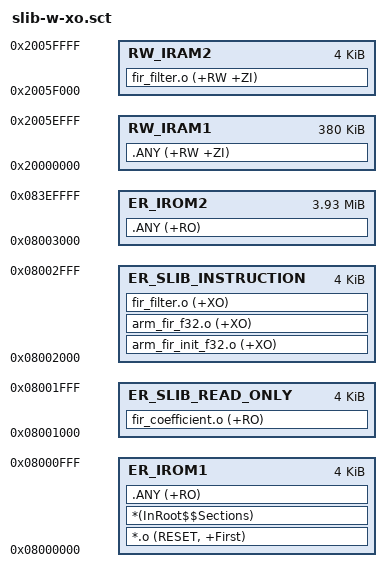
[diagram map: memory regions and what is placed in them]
; *************************************************************
; *** Scatter-Loading Description File generated by uVision ***
; *************************************************************

; this scatter file is used for at32f435zmt7 ( flash size is 4032kb, sector size is 4kb)

LR_IROM1 0x08000000 0x001000  {    ; load region size_region
  ER_IROM1 0x08000000 0x001000  {  ; load address = execution address
   *.o (RESET, +First)
   *(InRoot$$Sections)
   .ANY (+RO)
  }
  
  RW_IRAM1 0x20000000 0x0005F000  {  ; user RW data
   .ANY (+RW +ZI)
  }
  
  RW_IRAM2 0x2005F000 0x00001000  {  ; RAM used for slib code
   fir_filter.o (+RW +ZI) 
  }  
}

LR_SLIB_READ_ONLY 0x08001000 0x00001000  {    ; sLib read-only area
  ER_SLIB_READ_ONLY 0x08001000 0x00001000  {  
   fir_coefficient.o (+RO)   
  }
}

LR_SLIB_INSTRUCTION 0x08002000 0x00001000  {    ; slib instruction area
  ER_SLIB_INSTRUCTION 0x08002000 0x00001000  {  ; load address = execution address
	arm_fir_init_f32.o (+XO)
	arm_fir_f32.o (+XO)
	fir_filter.o (+XO)
  }
}

LR_IROM2 0x08003000 0x003ED000  {    ; user code area
  ER_IROM2 0x08003000 0x003ED000  {  ; load address = execution address
   .ANY (+RO)
  }
}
